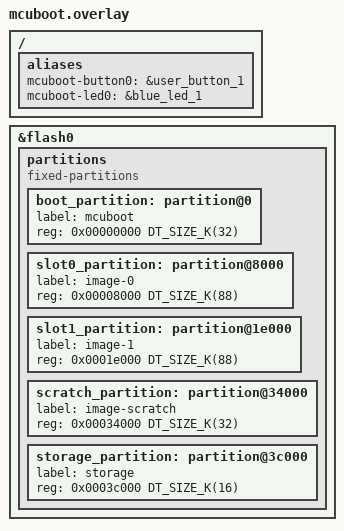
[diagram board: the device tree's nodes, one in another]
/{
    aliases{
        mcuboot-button0 = &user_button_1;
        mcuboot-led0 = &blue_led_1;
    };
};

/* 
 * Flash partition layout for STM32WL55JC (256KB total flash)
 * Optimized for MCUboot dual-slot with scratch area
 */
&flash0 {
    partitions {
        compatible = "fixed-partitions";
        #address-cells = <1>;
        #size-cells = <1>;

        /* MCUboot bootloader - 32KB */
        boot_partition: partition@0 {
            label = "mcuboot";
            reg = <0x00000000 DT_SIZE_K(32)>;
        };

        /* Primary application slot (slot0) - 88KB (reduced to make room) */
        slot0_partition: partition@8000 {
            label = "image-0";
            reg = <0x00008000 DT_SIZE_K(88)>;
        };

        /* Secondary application slot (slot1) - 88KB */
        slot1_partition: partition@1e000 {
            label = "image-1";
            reg = <0x0001e000 DT_SIZE_K(88)>;
        };

        /* Scratch area for image swapping - 32KB (needs to be same size as largest sector) */
        scratch_partition: partition@34000 {
            label = "image-scratch";
            reg = <0x00034000 DT_SIZE_K(32)>;
        };

        /* Storage area for persistent data - 16KB */
        storage_partition: partition@3c000 {
            label = "storage";
            reg = <0x0003c000 DT_SIZE_K(16)>;
        };
    };
};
